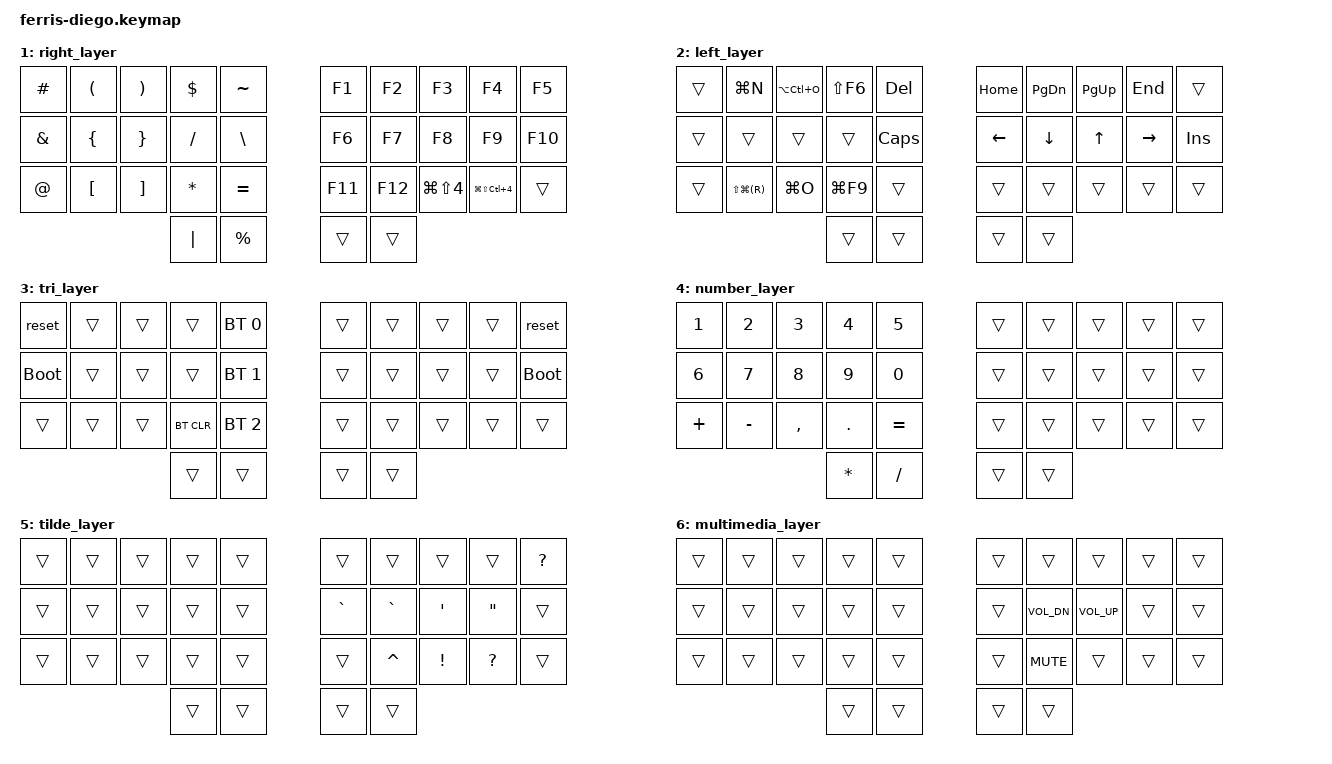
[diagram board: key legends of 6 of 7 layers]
// Copyright (c) 2022 The ZMK Contributors
// SPDX-License-Identifier: MIT

#include <behaviors.dtsi>
#include <dt-bindings/zmk/keys.h>
#include <dt-bindings/zmk/bt.h> 

// Home row mods macro 
#define HRML(k1,k2,k3,k4) &ht LCTRL k1  &ht LGUI k2  &ht LALT k3  &ht LSHFT k4
#define HRMR(k1,k2,k3,k4) &ht RSHFT k1  &ht RALT k2  &ht RGUI k3  &ht RCTRL k4

#define CAPW &kp LG(LS(N3)) // Capture whole screen 
#define CPYW &kp LG(LS(LC(N3))) // Copy whole screen 
#define CAPP &kp LG(LS(N4)) // Capture portion of screen   
#define CPYP &kp LG(LS(LC(N4))) // Copy portion of screen

#define RENAME &kp LS(F6)
#define IMPOR &kp LA(LC(O))
#define GENER &kp LG(N)
#define COMPI &kp LG(F9)
#define SEARCH &kp LS(LG((R)))
#define OPEN &kp LG(O)

#define COPIE &ht RG(C) C //copy
#define PAZT &ht RG(V) V //paste
#define KUT &ht RG(X) X //cut
#define UNNDO &ht RG(Z) Z //undo

#define CNTP &ht RG(T) T //chrome new tap
#define CRLT &ht RG(R) R //chrome reloat tab
#define CCTP &ht RG(W) W //chrome close tab



/ {
    behaviors {
        ht: hold_tap {
            label = "hold_tap";
            compatible = "zmk,behavior-hold-tap";
            #binding-cells = <2>;
            flavor = "balanced";
            tapping-term-ms = <200>;
            quick-tap-ms = <0>; 
            bindings = <&kp>, <&kp>;
        };        
    };

    conditional_layers {
        compatible = "zmk,conditional-layers";
        tri_layer {
            if-layers = <1 2>;
            then-layer = <3>;
        };
    };

    keymap {
        compatible = "zmk,keymap";
        default_layer {
            bindings = <
        //╭──────────┬──────────┬──────────┬──────────┬──────────╮   ╭──────────┬──────────┬──────────┬──────────┬──────────╮
        //│  Q ESC   │  W       │  E       │  R       │  T       │   │  Y       │  U       │  I       │  O       │  P       │
           &kb BT_CLR_ALL   &kb BT_NXT       &bt BT_PRV        CRLT     &lt 6 T        &lt 3 Y      &kp U      &kp I      &kp O      &kp P
        //├──────────┼──────────┼──────────┼──────────┼──────────┤   ├──────────┼──────────┼──────────┼──────────┼──────────┤
        //│  A       │  S       │  D       │  F       │  G       │   │  H       │  J       │  K       │  L       │ BSPC     │
            HRML(A,        S,         D,         F)     &lt 5 G        &lt 4 H    HRMR(J,        K,         L,        BSPC)
        //├──────────┼──────────┼──────────┼──────────┼──────────┤   ├──────────┼──────────┼──────────┼──────────┼──────────┤
        //│  Z       │  X       │  C       │  V       │  B       │   │  N       │  M       │ , <      │ . >      │  ; :     │
            UNNDO      KUT         COPIE      PAZT      &kp B          &kp N      &kp M      &kp COMMA  &kp DOT    &kp SEMI
        //╰──────────┴──────────┴──────────┼──────────┼──────────┤   ├──────────┼──────────┼──────────┴──────────┴──────────╯
                                            &ht RGUI TAB &lt 2 SPACE   &lt 1 ENTER  &ht RGUI MINUS
        //                                 ╰──────────┴──────────╯   ╰──────────┴──────────╯
            >;
        };

        right_layer {
            bindings = <
        //╭──────────┬──────────┬──────────┬──────────┬──────────╮   ╭──────────┬──────────┬──────────┬──────────┬──────────╮
        //│    #     │  (       │    )     │  $       │    ~     │   │   F1     │    F2    │   F3     │    F4    │   F5     │
            &kp HASH &kp LPAR &kp RPAR    &kp DOLLAR   &kp TILDE       &kp F1      &kp F2     &kp F3     &kp F4    &kp F5
        //├──────────┼──────────┼──────────┼──────────┼──────────┤   ├──────────┼──────────┼──────────┼──────────┼──────────┤
        //│    &     │   {      │    }     │  /       │    \     │   │   F6     │    F7    │   F8     │    F9    │   F10    │
            &kp AMPS &kp LBRC  &kp RBRC  &kp SLASH  &kp BSLH          &kp F6      &kp F7     &kp F8     &kp F9    &kp F10
        //├──────────┼──────────┼──────────┼──────────┼──────────┤   ├──────────┼──────────┼──────────┼──────────┼──────────┤
        //│    @     │  [       │    ]     │  *       │  =       │   │    F11   │    F12   │ PRSCRN   │  PRSCRN  │          │
             &kp AT  &kp LBKT  &kp RBKT  &kp ASTRK  &kp EQUAL         &kp F11      &kp F12   CAPP        CPYP       &trans 
        //╰──────────┴──────────┴──────────┼──────────┼──────────┤   ├──────────┼──────────┼──────────┴──────────┴──────────╯
                                            &kp PIPE  &kp PERCENT     &trans     &trans    
        //                                 ╰──────────┴──────────╯   ╰──────────┴──────────╯
            >;
        };

        left_layer {
            bindings = <
        //╭──────────┬──────────┬──────────┬──────────┬──────────╮   ╭──────────┬──────────┬──────────┬──────────┬──────────╮
        //│          │GENERATE  │IMPORTS   │ RENAME   │ DELETE   │   │  HOME    │ PG DOWN  │ PG UP    │  END     │          │
            &trans     GENER      IMPOR      RENAME     &kp DEL        &kp HOME  &kp PG_DN  &kp PG_UP   &kp END    &trans
        //├──────────┼──────────┼──────────┼──────────┼──────────┤   ├──────────┼──────────┼──────────┼──────────┼──────────┤
        //│          │          │          │          │CAPS LOCK │   │  LEFT    │  DOWN    │   UP     │   RIGH   │ INSERT   │
            &trans     &trans     &trans     &trans     &kp CAPS      &kp LEFT   &kp DOWN    &kp UP    &kp RIGHT   &kp INS
        //├──────────┼──────────┼──────────┼──────────┼──────────┤   ├──────────┼──────────┼──────────┼──────────┼──────────┤
        //│          │ SEARCH   │  OPEN    │ COMPILE  │          │   │          │          │          │          │          │
            &trans     SEARCH      OPEN       COMPI     &trans         &trans      &trans    &trans      &trans     &trans
        //╰──────────┴──────────┴──────────┼──────────┼──────────┤   ├──────────┼──────────┼──────────┴──────────┴──────────╯
                                             &trans     &trans         &trans     &trans
        //                                 ╰──────────┴──────────╯   ╰──────────┴──────────╯
            >;
        };


        tri_layer {
            bindings = <
        //╭──────────┬──────────┬──────────┬──────────┬──────────╮   ╭──────────┬──────────┬──────────┬──────────┬──────────╮
        //│ RESET    │          │          │          │PROFILE 0 │   │          │          │          │          │  RESET   │
            &reset     &trans     &trans     &trans    &bt BT_SEL 0    &trans     &trans     &trans     &trans      &reset
        //├──────────┼──────────┼──────────┼──────────┼──────────┤   ├──────────┼──────────┼──────────┼──────────┼──────────┤
        //│BOOTLOADER│          │          │          │PROFILE 1 │   │          │          │          │          │BOOTLOADER│
          &bootloader  &trans     &trans     &trans    &bt BT_SEL 1    &trans     &trans     &trans     &trans    &bootloader
        //├──────────┼──────────┼──────────┼──────────┼──────────┤   ├──────────┼──────────┼──────────┼──────────┼──────────┤
        //│          │          │          │ CLEAR BT │PROFILE 2 │   │          │          │          │          │          │
            &trans     &trans     &trans    &bt BT_CLR &bt BT_SEL 2    &trans     &trans     &trans     &trans     &trans
        //╰──────────┴──────────┴──────────┼──────────┼──────────┤   ├──────────┼──────────┼──────────┴──────────┴──────────╯
                                             &trans     &trans         &trans     &trans
        //                                 ╰──────────┴──────────╯   ╰──────────┴──────────╯
            >;
        };


        number_layer {
            bindings = <
        //╭──────────┬──────────┬──────────┬──────────┬──────────╮   ╭──────────┬──────────┬──────────┬──────────┬──────────╮
        //│    1     │  2       │  3       │  4       │  5       │   │          │          │          │          │          │
             &kp N1     &kp N2    &kp N3      &kp N4     &kp N5         &trans     &trans     &trans     &trans     &trans
        //├──────────┼──────────┼──────────┼──────────┼──────────┤   ├──────────┼──────────┼──────────┼──────────┼──────────┤
        //│  6       │  7       │  8       │  9       │  0       │   │          │          │          │          │          │
            &kp N6     &kp N7    &kp N8      &kp N9     &kp N0          &trans     &trans     &trans     &trans     &trans
        //├──────────┼──────────┼──────────┼──────────┼──────────┤   ├──────────┼──────────┼──────────┼──────────┼──────────┤
        //│     +    │    -     │    ,     │    .     │    =     │   │          │          │          │          │          │
           &kp PLUS  &kp MINUS  &kp COMMA  &kp DOT  &kp EQUAL       &trans     &trans     &trans     &trans     &trans
        //╰──────────┴──────────┴──────────┼──────────┼──────────┤   ├──────────┼──────────┼──────────┴──────────┴──────────╯
                                             &kp ASTRK  &kp SLASH    &trans     &trans
        //                                 ╰──────────┴──────────╯   ╰──────────┴──────────╯
            >;
        };

       tilde_layer {
            bindings = <
        //╭──────────┬──────────┬──────────┬──────────┬──────────╮   ╭──────────┬──────────┬──────────┬──────────┬──────────╮
        //│          │          │          │          │          │   │          │          │          │          │   ?      │
             &trans     &trans     &trans     &trans     &trans         &trans    &trans    &trans     &trans    &kp QMARK
        //├──────────┼──────────┼──────────┼──────────┼──────────┤   ├──────────┼──────────┼──────────┼──────────┼──────────┤
        //│          │          │          │          │          │   │   `      │    `     │     '    │    "     │          │
            &trans     &trans     &trans     &trans     &trans       &kp GRAVE  &kp GRAVE &kp APOS    &kp DQT    &trans
        //├──────────┼──────────┼──────────┼──────────┼──────────┤   ├──────────┼──────────┼──────────┼──────────┼──────────┤
        //│          │          │          │          │          │   │          │    ^     │     !    │     ?     │          │
            &trans     &trans     &trans     &trans     &trans           &trans   &kp CARET   &kp EXCL &kp QMARK     &trans
        //╰──────────┴──────────┴──────────┼──────────┼──────────┤   ├──────────┼──────────┼──────────┴──────────┴──────────╯
                                             &trans     &trans          &trans     &trans
        //                                 ╰──────────┴──────────╯   ╰──────────┴──────────╯
            >;
        };

       multimedia_layer {
            bindings = <
        //╭──────────┬──────────┬──────────┬──────────┬──────────╮   ╭──────────┬──────────┬──────────┬──────────┬──────────╮
        //│          │          │          │          │          │   │          │          │          │          │          │
            &trans     &trans     &trans     &trans     &trans         &trans     &trans     &trans     &trans     &trans
        //├──────────┼──────────┼──────────┼──────────┼──────────┤   ├──────────┼──────────┼──────────┼──────────┼──────────┤
        //│          │          │          │          │          │   │          │ VOL DOWN │  VOL UP  │          │          │
             &trans     &trans     &trans     &trans     &trans        &trans   &kp K_VOL_DN &kp K_VOL_UP &trans     &trans
        //├──────────┼──────────┼──────────┼──────────┼──────────┤   ├──────────┼──────────┼──────────┼──────────┼──────────┤
        //│          │          │          │          │          │   │          │  MUTE    │          │          │          │
            &trans     &trans     &trans     &trans     &trans         &trans    &kp K_MUTE    &trans     &trans     &trans
        //╰──────────┴──────────┴──────────┼──────────┼──────────┤   ├──────────┼──────────┼──────────┴──────────┴──────────╯
                                             &trans     &trans         &trans     &trans
        //                                 ╰──────────┴──────────╯   ╰──────────┴──────────╯
            >;
        };
    };
};
